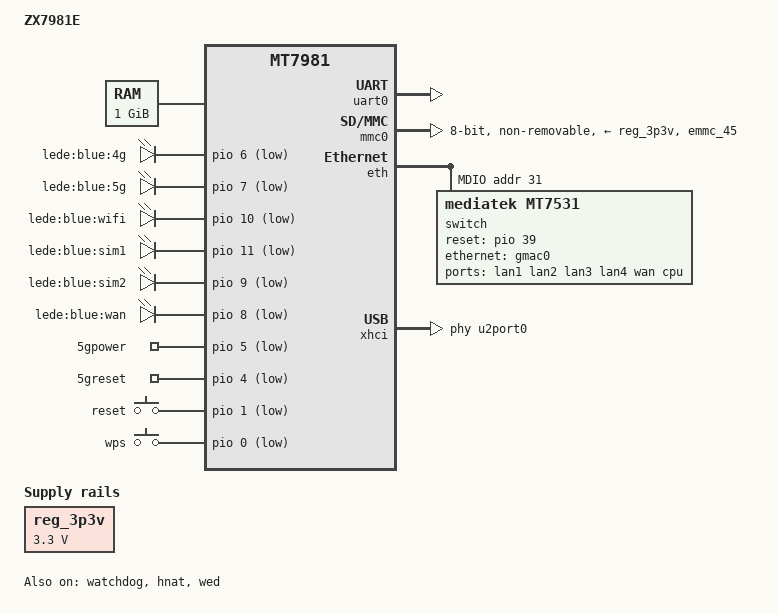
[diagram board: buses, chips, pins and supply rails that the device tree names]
/dts-v1/;
#include "mt7981.dtsi"

#include <dt-bindings/input/input.h>

/ {
	model = "ZX7981E";
	compatible = "ZX7981E";
	chosen {
		bootargs = "console=ttyS0,115200n1 loglevel=8  \
				earlycon=uart8250,mmio32,0x11002000 \
				root=PARTLABEL=rootfs rootwait rootfstype=squashfs,f2fs";
	};

	memory {
		// 1024MB
		reg = <0 0x40000000 0 0x40000000>;
	};

	reg_3p3v: regulator-3p3v {
		compatible = "regulator-fixed";
		regulator-name = "fixed-3.3V";
		regulator-min-microvolt = <3300000>;
		regulator-max-microvolt = <3300000>;
		regulator-boot-on;
		regulator-always-on;
	};

	gpio-leds {
		compatible = "gpio-leds";

		4g {
			label = "lede:blue:4g";
			gpios = <&pio 6 1>;
			linux,default-trigger = "none";
			default-state = "off";
		};

		5g {
			label = "lede:blue:5g";
			gpios = <&pio 7 1>;
			linux,default-trigger = "none";
			default-state = "off";
		};

		wifi {
			label = "lede:blue:wifi";
			gpios = <&pio 10 1>;
			linux,default-trigger = "none";
			default-state = "off";
		};

		sim1 {
			label = "lede:blue:sim1";
			gpios = <&pio 11 1>;
			linux,default-trigger = "none";
			default-state = "off";
		};

		sim2 {
			label = "lede:blue:sim2";
			gpios = <&pio 9 1>;
			linux,default-trigger = "none";
			default-state = "off";
		};

		wan {
			label = "lede:blue:wan";
			gpios = <&pio 8 1>;
			linux,default-trigger = "none";
			default-state = "off";
		};
	};

	gpio-export {
		compatible = "gpio-export";
		5gpower {
			gpio-export,name = "5gpower";
			gpio-export,output = <0>; // OUT_INIT_LOW
			gpios = <&pio 5 1>;    // GPIO 25, ACTIVE_LOW
		};

		5greset {
			gpio-export,name = "5greset";
			gpio-export,output = <1>; // OUT_INIT_LOW
			gpios = <&pio 4 1>;    // GPIO 2, ACTIVE_LOW
		};
	};

	gpio-keys-polled {
		compatible = "gpio-keys-polled";
		#address-cells = <1>;
		#size-cells = <0>;
		poll-interval = <20>;

		reset {
			label = "reset";
			gpios = <&pio 1 1>;
			linux,code = <KEY_RESTART>;
		};

		wps {
			label = "wps";
			gpios = <&pio 0 1>;
			linux,code = <KEY_WPS_BUTTON>;
		};
	};
};

&uart0 {
	status = "okay";
};

&watchdog {
	status = "okay";
};

&mmc0 {
         pinctrl-names = "default", "state_uhs";
         pinctrl-0 = <&mmc0_pins_default>;
         pinctrl-1 = <&mmc0_pins_uhs>;
         bus-width = <8>;
         max-frequency = <52000000>;
         cap-mmc-highspeed;
         vmmc-supply = <&reg_3p3v>;
         non-removable;
         status = "okay";
};

&eth {
        status = "okay";

        gmac0: mac@0 {
                compatible = "mediatek,eth-mac";
                reg = <0>;
                phy-mode = "2500base-x";

                fixed-link {
                        speed = <2500>;
                        full-duplex;
                        pause;
                };
        };

        mdio: mdio-bus {
                #address-cells = <1>;
                #size-cells = <0>;

		switch@0 {
                        compatible = "mediatek,mt7531";
                        reg = <31>;
                        reset-gpios = <&pio 39 0>;

                        ports {
                                #address-cells = <1>;
                                #size-cells = <0>;

                                port@0 {
                                        reg = <0>;
                                        label = "lan1";
                                };

                                port@1 {
                                        reg = <1>;
                                        label = "lan2";
                                };

                                port@2 {
                                        reg = <2>;
                                        label = "lan3";
                                };

                        	port@3 {
                                	reg = <3>;
	                                label = "lan4";
        	                };

                        	port@4 {
                                	reg = <4>;
	                                label = "wan";
        	                };

                                port@6 {
                                        reg = <6>;
                                        label = "cpu";
                                        ethernet = <&gmac0>;
                                        phy-mode = "2500base-x";

                                        fixed-link {
                                                speed = <2500>;
                                                full-duplex;
                                                pause;
                                        };
                                };
                        };
                };
        };
};


&hnat {
	mtketh-wan = "wan";
	mtketh-lan = "lan";
	mtketh-max-gmac = <1>;
	status = "okay";
};

&pio {
	mmc0_pins_default: mmc0-pins-default {
		mux {
			function = "flash";
			groups = "emmc_45";
		};
	};

	mmc0_pins_uhs: mmc0-pins-uhs {
		mux {
			function = "flash";
			groups = "emmc_45";
		};
	};
};

&xhci {
	mediatek,u3p-dis-msk = <0x0>;
	phys = <&u2port0 PHY_TYPE_USB2>,
	       <&u3port0 PHY_TYPE_USB3>;
        status = "okay";
};

&wed {
	dy_txbm_enable = "true";
	dy_txbm_budget = <8>;
	txbm_init_sz = <8>;
	txbm_max_sz = <32>;
	status = "okay";
};
